# N32G003 register map
Vendor: Nationstech Ltd.; File version: 1.0
Registers are 32-bit, read-write, reset 0x0 unless marked. A register's access mark holds for its fields unless they carry their own. Offsets are from the block's base; [hi:lo] are bit positions; {n}, {i} and the like mark numbered series.

## GPIOA — General purpose I/O
Base 0x40001C00
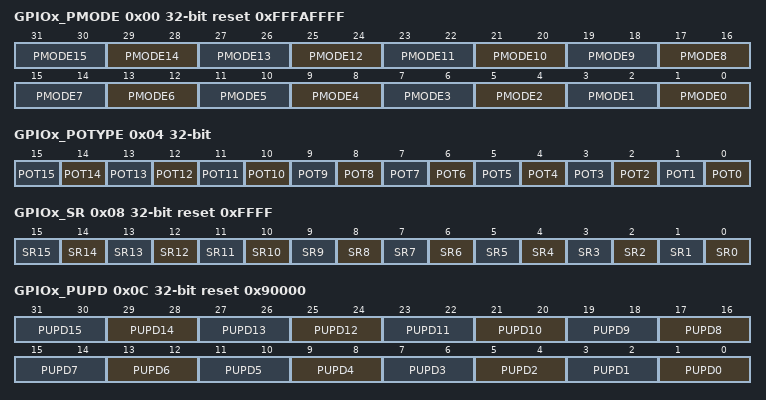
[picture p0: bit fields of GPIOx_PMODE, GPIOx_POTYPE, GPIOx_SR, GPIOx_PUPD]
0x00 GPIOx_PMODE reset 0xFFFAFFFF
  [2n+1:2n] PMODE{n} (n=0..15)
0x04 GPIOx_POTYPE
  [n] POT{n} (n=0..15)
0x08 GPIOx_SR reset 0xFFFF
  [n] SR{n} (n=0..15)
0x0C GPIOx_PUPD reset 0x90000
  [2n+1:2n] PUPD{n} (n=0..15)
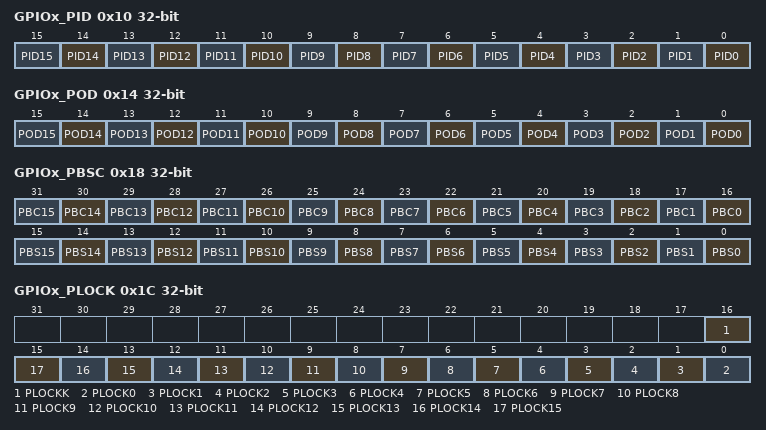
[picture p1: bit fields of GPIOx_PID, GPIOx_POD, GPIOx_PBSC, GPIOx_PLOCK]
0x10 GPIOx_PID
  [n] PID{n} (n=0..15)
0x14 GPIOx_POD
  [n] POD{n} (n=0..15)
0x18 GPIOx_PBSC
  [n+16] PBC{n} (n=0..15), [n] PBS{n} (n=0..15)
0x1C GPIOx_PLOCK
  [16] PLOCKK, [n] PLOCK{n} (n=0..15)
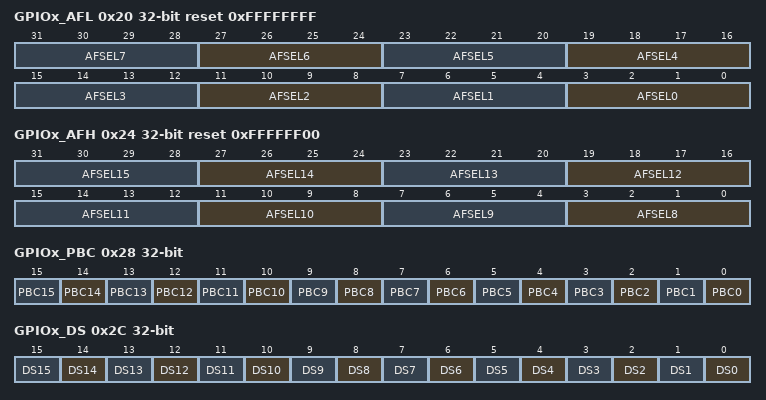
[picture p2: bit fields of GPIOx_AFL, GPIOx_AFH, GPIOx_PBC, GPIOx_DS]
0x20 GPIOx_AFL reset 0xFFFFFFFF
  [4n+3:4n] AFSEL{n} (n=0..7)
0x24 GPIOx_AFH reset 0xFFFFFF00
  [4n-29:4n-32] AFSEL{n} (n=8..15)
0x28 GPIOx_PBC
  [n] PBC{n} (n=0..15)
0x2C GPIOx_DS
  [n] DS{n} (n=0..15)

## GPIOB — General purpose I/O
Base 0x40002000
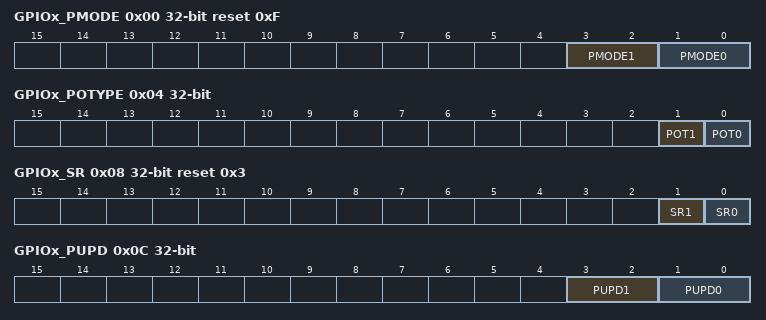
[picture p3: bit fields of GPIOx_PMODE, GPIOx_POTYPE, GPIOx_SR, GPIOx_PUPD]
0x00 GPIOx_PMODE reset 0xF
  [3:2] PMODE1, [1:0] PMODE0
0x04 GPIOx_POTYPE
  [1] POT1, [0] POT0
0x08 GPIOx_SR reset 0x3
  [1] SR1, [0] SR0
0x0C GPIOx_PUPD
  [3:2] PUPD1, [1:0] PUPD0
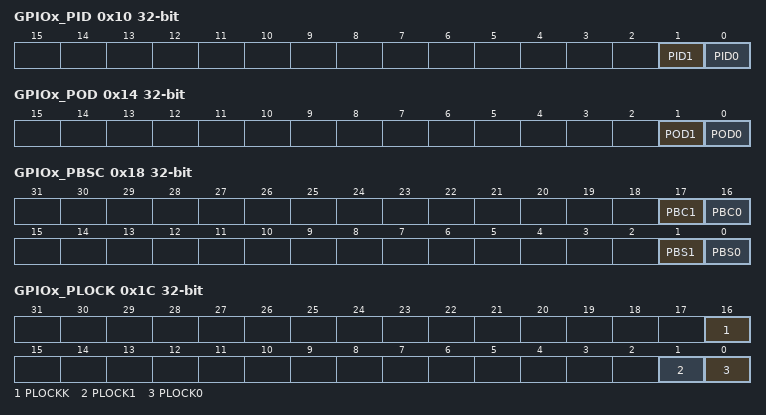
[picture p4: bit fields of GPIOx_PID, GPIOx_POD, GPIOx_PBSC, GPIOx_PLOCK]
0x10 GPIOx_PID
  [1] PID1, [0] PID0
0x14 GPIOx_POD
  [1] POD1, [0] POD0
0x18 GPIOx_PBSC
  [17] PBC1, [16] PBC0, [1] PBS1, [0] PBS0
0x1C GPIOx_PLOCK
  [16] PLOCKK, [1] PLOCK1, [0] PLOCK0
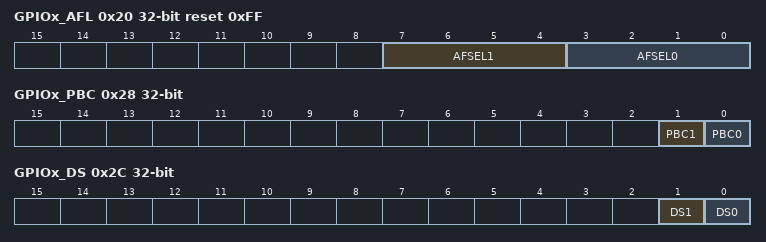
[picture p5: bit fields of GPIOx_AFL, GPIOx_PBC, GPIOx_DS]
0x20 GPIOx_AFL reset 0xFF
  [7:4] AFSEL1, [3:0] AFSEL0
0x28 GPIOx_PBC
  [1] PBC1, [0] PBC0
0x2C GPIOx_DS
  [1] DS1, [0] DS0

## AFIO — Alternate function I/O
Base 0x40001400
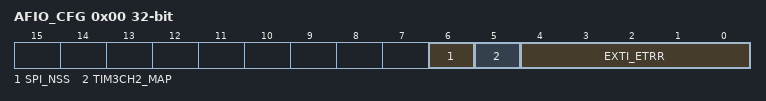
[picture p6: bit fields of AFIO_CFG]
0x00 AFIO_CFG
  [6] SPI_NSS, [5] TIM3CH2_MAP, [4:0] EXTI_ETRR

## I2C — Inter integrated circuit
Base 0x40005400
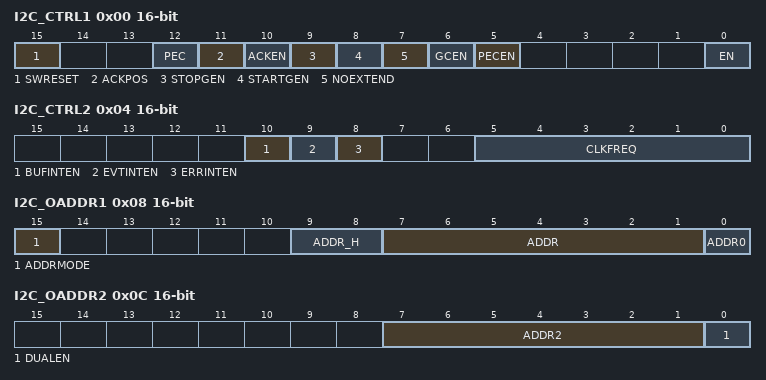
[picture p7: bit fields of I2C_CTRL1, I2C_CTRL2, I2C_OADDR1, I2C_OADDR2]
0x00 I2C_CTRL1 16-bit
  [15] SWRESET, [12] PEC, [11] ACKPOS, [10] ACKEN, [9] STOPGEN, [8] STARTGEN, [7] NOEXTEND, [6] GCEN, [5] PECEN, [0] EN
0x04 I2C_CTRL2 16-bit
  [10] BUFINTEN, [9] EVTINTEN, [8] ERRINTEN, [5:0] CLKFREQ
0x08 I2C_OADDR1 16-bit
  [15] ADDRMODE, [9:8] ADDR_H, [7:1] ADDR, [0] ADDR0
0x0C I2C_OADDR2 16-bit
  [7:1] ADDR2, [0] DUALEN
0x10 I2C_DAT 16-bit
  [7:0] DATA
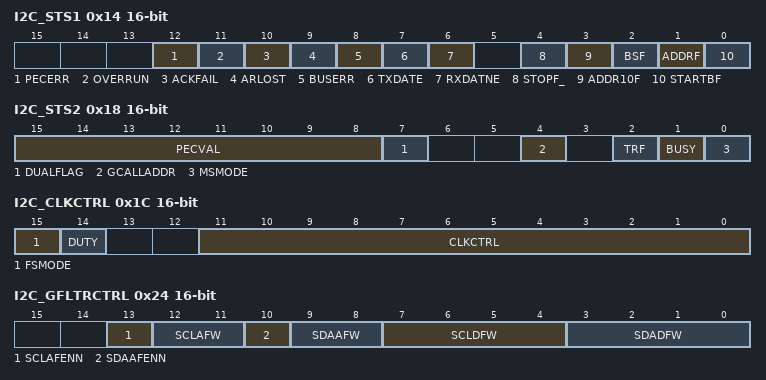
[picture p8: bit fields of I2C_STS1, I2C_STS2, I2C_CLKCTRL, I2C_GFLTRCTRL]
0x14 I2C_STS1 16-bit
  [12] PECERR, [11] OVERRUN, [10] ACKFAIL, [9] ARLOST, [8] BUSERR, [7] TXDATE, [6] RXDATNE, [4] STOPF_, [3] ADDR10F, [2] BSF, [1] ADDRF, [0] STARTBF
0x18 I2C_STS2 16-bit
  [15:8] PECVAL, [7] DUALFLAG, [4] GCALLADDR, [2] TRF, [1] BUSY, [0] MSMODE
0x1C I2C_CLKCTRL 16-bit
  [15] FSMODE, [14] DUTY, [11:0] CLKCTRL
0x20 I2C_TMRISE 16-bit reset 0x2
  [5:0] TMRISE
0x24 I2C_GFLTRCTRL 16-bit
  [13] SCLAFENN, [12:11] SCLAFW, [10] SDAAFENN, [9:8] SDAAFW, [7:4] SCLDFW, [3:0] SDADFW
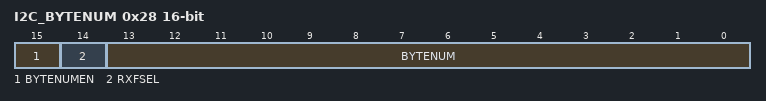
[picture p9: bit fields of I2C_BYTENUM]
0x28 I2C_BYTENUM 16-bit (reset mask 0x3F)
  [15] BYTENUMEN, [14] RXFSEL, [13:0] BYTENUM

## IWDG — Independent watchdog
Base 0x40002C00
0x00 IWDG_KEY
  [15:0] KEYV
0x04 IWDG_PREDIV
  [2:0] PD
0x08 IWDG_RELV reset 0xFFF
  [11:0] REL
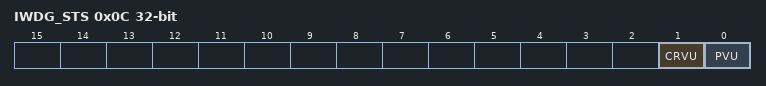
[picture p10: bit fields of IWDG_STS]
0x0C IWDG_STS
  [1] CRVU, [0] PVU
0x10 IWDG_FREEZE
  [0] FREEZE

## PWR — Power control
Base 0x40007000
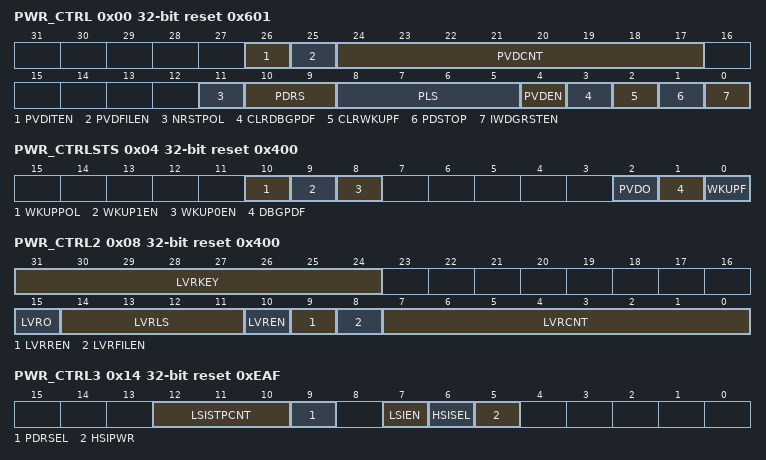
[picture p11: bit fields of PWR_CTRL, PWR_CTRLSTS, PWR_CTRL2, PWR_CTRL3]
0x00 PWR_CTRL reset 0x601 (reset mask 0x7FE)
  [26] PVDITEN, [25] PVDFILEN, [24:17] PVDCNT, [11] NRSTPOL, [10:9] PDRS, [8:5] PLS, [4] PVDEN, [3] CLRDBGPDF, [2] CLRWKUPF, [1] PDSTOP, [0] IWDGRSTEN
0x04 PWR_CTRLSTS reset 0x400
  [10] WKUPPOL, [9] WKUP1EN, [8] WKUP0EN, [2] PVDO, [1] DBGPDF, [0] WKUPF
0x08 PWR_CTRL2 reset 0x400 (reset mask 0x400)
  [31:24] LVRKEY, [15] LVRO, [14:11] LVRLS, [10] LVREN, [9] LVRREN, [8] LVRFILEN, [7:0] LVRCNT
0x14 PWR_CTRL3 reset 0xEAF (reset mask 0x80)
  [12:10] LSISTPCNT, [9] PDRSEL, [7] LSIEN, [6] HSISEL, [5] HSIPWR
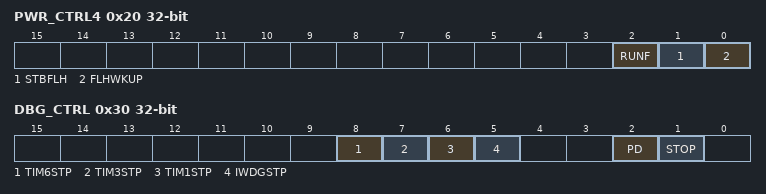
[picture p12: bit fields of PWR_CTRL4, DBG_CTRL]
0x20 PWR_CTRL4 (reset mask 0x73)
  [2] RUNF — LPRUNFLH
  [1] STBFLH — STBFLASH
  [0] FLHWKUP
0x24 PWR_CTRL5 reset 0x4 (reset mask 0xC0)
  [3:2] STPMRSEL
0x28 PWR_CTRL6 (reset mask 0xC0)
  [3:2] STPMREN
0x30 DBG_CTRL (reset mask 0x79F06)
  [8] TIM6STP, [7] TIM3STP, [6] TIM1STP, [5] IWDGSTP, [2] PD, [1] STOP

## RCC — Reset and clock control
Base 0x40021000
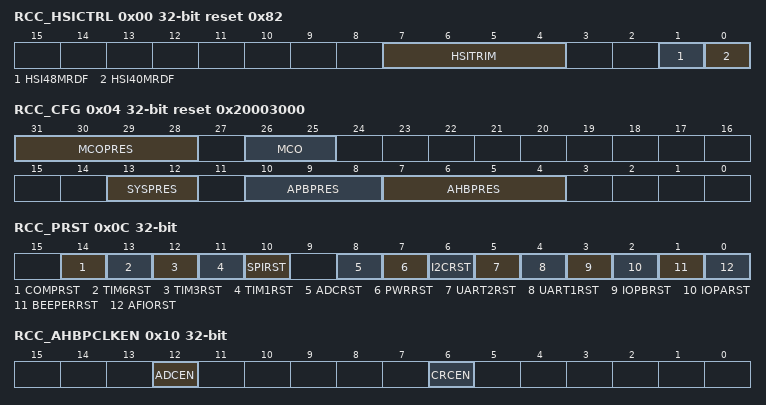
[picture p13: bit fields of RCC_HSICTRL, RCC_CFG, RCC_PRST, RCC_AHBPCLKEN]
0x00 RCC_HSICTRL reset 0x82
  [7:4] HSITRIM, [1] HSI48MRDF, [0] HSI40MRDF
0x04 RCC_CFG reset 0x20003000
  [31:28] MCOPRES, [26:25] MCO, [13:12] SYSPRES, [10:8] APBPRES, [7:4] AHBPRES
0x0C RCC_PRST
  [14] COMPRST, [13] TIM6RST, [12] TIM3RST, [11] TIM1RST, [10] SPIRST, [8] ADCRST, [7] PWRRST, [6] I2CRST, [5] UART2RST, [4] UART1RST, [3] IOPBRST, [2] IOPARST, [1] BEEPERRST, [0] AFIORST
0x10 RCC_AHBPCLKEN
  [12] ADCEN, [6] CRCEN
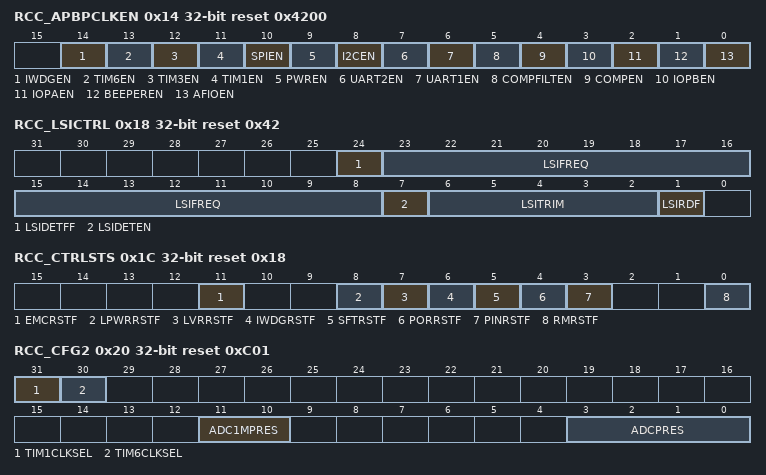
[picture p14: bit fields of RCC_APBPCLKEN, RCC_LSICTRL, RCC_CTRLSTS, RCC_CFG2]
0x14 RCC_APBPCLKEN reset 0x4200
  [14] IWDGEN, [13] TIM6EN, [12] TIM3EN, [11] TIM1EN, [10] SPIEN, [9] PWREN, [8] I2CEN, [7] UART2EN, [6] UART1EN, [5] COMPFILTEN, [4] COMPEN, [3] IOPBEN, [2] IOPAEN, [1] BEEPEREN, [0] AFIOEN
0x18 RCC_LSICTRL reset 0x42
  [24] LSIDETFF, [23:8] LSIFREQ, [7] LSIDETEN, [6:2] LSITRIM, [1] LSIRDF
0x1C RCC_CTRLSTS reset 0x18
  [11] EMCRSTF, [8] LPWRRSTF, [7] LVRRSTF, [6] IWDGRSTF, [5] SFTRSTF, [4] PORRSTF, [3] PINRSTF, [0] RMRSTF
0x20 RCC_CFG2 reset 0xC01
  [31] TIM1CLKSEL, [30] TIM6CLKSEL, [11:10] ADC1MPRES, [3:0] ADCPRES
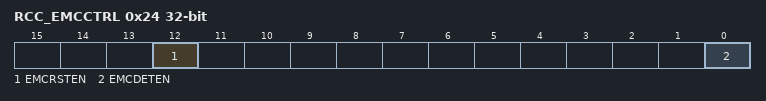
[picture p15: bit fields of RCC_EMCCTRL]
0x24 RCC_EMCCTRL
  [12] EMCRSTEN, [0] EMCDETEN
